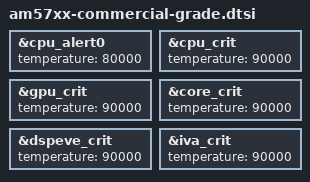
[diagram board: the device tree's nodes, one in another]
&cpu_alert0 {
	temperature = <80000>;  
};
&cpu_crit {
	temperature = <90000>;  
};
&gpu_crit {
	temperature = <90000>;  
};
&core_crit {
	temperature = <90000>;  
};
&dspeve_crit {
	temperature = <90000>;  
};
&iva_crit {
	temperature = <90000>;  
};
